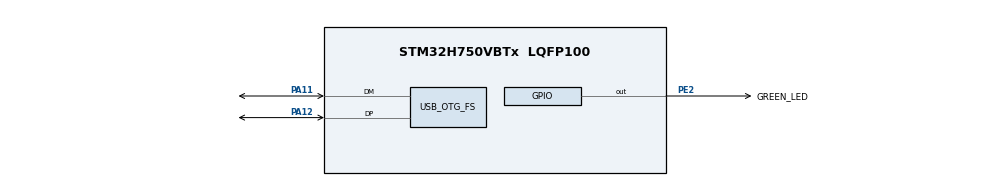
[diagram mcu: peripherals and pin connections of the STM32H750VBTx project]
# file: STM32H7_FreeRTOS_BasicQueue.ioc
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FREERTOS.Queues01=messageQueue,4,uint8_t,0,Dynamic,NULL,NULL
FREERTOS.Tasks01=receive,24,256,receiveTask,Default,NULL,Dynamic,NULL,NULL;transmit,24,256,transmitTask,Default,NULL,Dynamic,NULL,NULL
Mcu.Family=STM32H7
Mcu.Name=STM32H750VBTx
Mcu.Package=LQFP100
NVIC.OTG_FS_IRQn=true\:5\:0\:false\:false\:true\:true\:false\:true\:true
NVIC.PriorityGroup=NVIC_PRIORITYGROUP_4
NVIC.TIM6_DAC_IRQn=true\:15\:0\:false\:false\:true\:false\:false\:true\:true
NVIC.TimeBase=TIM6_DAC_IRQn
NVIC.TimeBaseIP=TIM6
PA11.Mode=Device_Only
PA11.Signal=USB_OTG_FS_DM
PA12.Mode=Device_Only
PA12.Signal=USB_OTG_FS_DP
PE2.GPIO_Label=GREEN_LED
PE2.Signal=GPIO_Output
ProjectManager.HeapSize=0x200
ProjectManager.StackSize=0x400
ProjectManager.TargetToolchain=Makefile
RCC.ADCFreq_Value=129000000
RCC.APB1Freq_Value=64000000
RCC.APB2Freq_Value=64000000
RCC.APB3Freq_Value=64000000
RCC.APB4Freq_Value=64000000
RCC.CortexFreq_Value=64000000
RCC.HCLKFreq_Value=64000000
RCC.SYSCLKFreq_VALUE=64000000
RCC.USBCLockSelection=RCC_USBCLKSOURCE_HSI48
RCC.USBFreq_Value=48000000
USB_DEVICE.CLASS_NAME_FS=CDC
USB_DEVICE.VirtualMode-CDC_FS=Cdc
USB_DEVICE.VirtualModeFS=Cdc_FS
USB_OTG_FS.VirtualMode=Device_Only
VP_FREERTOS_VS_CMSIS_V2.Mode=CMSIS_V2
VP_SYS_VS_tim6.Mode=TIM6
VP_USB_DEVICE_VS_USB_DEVICE_CDC_FS.Mode=CDC_FS
board=custom

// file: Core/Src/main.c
/* USER CODE BEGIN Header */
/**
  ******************************************************************************
  * @file           : main.c
  * @brief          : Main program body
  ******************************************************************************
  * @attention
  *
  * Copyright (c) 2024 STMicroelectronics.
  * All rights reserved.
  *
  * This software is licensed under terms that can be found in the LICENSE file
  * in the root directory of this software component.
  * If no LICENSE file comes with this software, it is provided AS-IS.
  *
  ******************************************************************************
  */
/* USER CODE END Header */
#include "main.h"
#include "cmsis_os.h"
#include "usb_device.h"
#include "usbd_cdc_if.h"

/* Definitions for receive */
osThreadId_t receiveHandle;
const osThreadAttr_t receive_attributes = {
  .name = "receive",
  .stack_size = 256 * 4,
  .priority = (osPriority_t) osPriorityNormal,
};
/* Definitions for transmit */
osThreadId_t transmitHandle;
const osThreadAttr_t transmit_attributes = {
  .name = "transmit",
  .stack_size = 256 * 4,
  .priority = (osPriority_t) osPriorityNormal,
};
/* Definitions for messageQueue */
osMessageQueueId_t messageQueueHandle;
const osMessageQueueAttr_t messageQueue_attributes = {
  .name = "messageQueue"
};

void SystemClock_Config(void);
static void MX_GPIO_Init(void);
void receiveTask(void *argument);
void transmitTask(void *argument);

int main(void)
{

  /* MCU Configuration--------------------------------------------------------*/

  /* Reset of all peripherals, Initializes the Flash interface and the Systick. */
  HAL_Init();

  /* Configure the system clock */
  SystemClock_Config();

  /* Initialize all configured peripherals */
  MX_GPIO_Init();

  /* Init scheduler */
  osKernelInitialize();

  /* Create the queue(s) */
  /* creation of messageQueue */
  messageQueueHandle = osMessageQueueNew (4, sizeof(uint8_t), &messageQueue_attributes);

  /* Create the thread(s) */
  /* creation of receive */
  receiveHandle = osThreadNew(receiveTask, NULL, &receive_attributes);

  /* creation of transmit */
  transmitHandle = osThreadNew(transmitTask, NULL, &transmit_attributes);

  /* Start scheduler */
  osKernelStart();

  /* We should never get here as control is now taken by the scheduler */
  /* Infinite loop */
  while (1)
  {

  }
}

void SystemClock_Config(void)
{
  RCC_OscInitTypeDef RCC_OscInitStruct = {0};
  RCC_ClkInitTypeDef RCC_ClkInitStruct = {0};

  /** Supply configuration update enable
  */
  HAL_PWREx_ConfigSupply(PWR_LDO_SUPPLY);

  /** Configure the main internal regulator output voltage
  */
  __HAL_PWR_VOLTAGESCALING_CONFIG(PWR_REGULATOR_VOLTAGE_SCALE3);

  while(!__HAL_PWR_GET_FLAG(PWR_FLAG_VOSRDY)) {}

  /** Initializes the RCC Oscillators according to the specified parameters
  * in the RCC_OscInitTypeDef structure.
  */
  RCC_OscInitStruct.OscillatorType = RCC_OSCILLATORTYPE_HSI48|RCC_OSCILLATORTYPE_HSI;
  RCC_OscInitStruct.HSIState = RCC_HSI_DIV1;
  RCC_OscInitStruct.HSICalibrationValue = RCC_HSICALIBRATION_DEFAULT;
  RCC_OscInitStruct.HSI48State = RCC_HSI48_ON;
  RCC_OscInitStruct.PLL.PLLState = RCC_PLL_NONE;
  if (HAL_RCC_OscConfig(&RCC_OscInitStruct) != HAL_OK)
  {
    Error_Handler();
  }

  /** Initializes the CPU, AHB and APB buses clocks
  */
  RCC_ClkInitStruct.ClockType = RCC_CLOCKTYPE_HCLK|RCC_CLOCKTYPE_SYSCLK
                              |RCC_CLOCKTYPE_PCLK1|RCC_CLOCKTYPE_PCLK2
                              |RCC_CLOCKTYPE_D3PCLK1|RCC_CLOCKTYPE_D1PCLK1;
  RCC_ClkInitStruct.SYSCLKSource = RCC_SYSCLKSOURCE_HSI;
  RCC_ClkInitStruct.SYSCLKDivider = RCC_SYSCLK_DIV1;
  RCC_ClkInitStruct.AHBCLKDivider = RCC_HCLK_DIV1;
  RCC_ClkInitStruct.APB3CLKDivider = RCC_APB3_DIV1;
  RCC_ClkInitStruct.APB1CLKDivider = RCC_APB1_DIV1;
  RCC_ClkInitStruct.APB2CLKDivider = RCC_APB2_DIV1;
  RCC_ClkInitStruct.APB4CLKDivider = RCC_APB4_DIV1;

  if (HAL_RCC_ClockConfig(&RCC_ClkInitStruct, FLASH_LATENCY_1) != HAL_OK)
  {
    Error_Handler();
  }
}

static void MX_GPIO_Init(void)
{
  GPIO_InitTypeDef GPIO_InitStruct = {0};

  /* GPIO Ports Clock Enable */
  __HAL_RCC_GPIOE_CLK_ENABLE();
  __HAL_RCC_GPIOA_CLK_ENABLE();

  /*Configure GPIO pin Output Level */
  HAL_GPIO_WritePin(GREEN_LED_GPIO_Port, GREEN_LED_Pin, GPIO_PIN_RESET);

  /*Configure GPIO pin : GREEN_LED_Pin */
  GPIO_InitStruct.Pin = GREEN_LED_Pin;
  GPIO_InitStruct.Mode = GPIO_MODE_OUTPUT_PP;
  GPIO_InitStruct.Pull = GPIO_NOPULL;
  GPIO_InitStruct.Speed = GPIO_SPEED_FREQ_LOW;
  HAL_GPIO_Init(GREEN_LED_GPIO_Port, &GPIO_InitStruct);

}

void receiveTask(void *argument)
{
  /* init code for USB_DEVICE */
  MX_USB_DEVICE_Init();
  /* USER CODE BEGIN 5 */
  uint8_t res = 0;
  char buffer[50];
  /* Infinite loop */
  for(;;)
  {
    snprintf(buffer, sizeof(buffer), "Data: %d\r\n", res);
    CDC_Transmit_FS((uint8_t*)buffer, strlen(buffer));
    osMessageQueueGet(messageQueueHandle, &res, NULL, osWaitForever);
    osDelay(1000);
  }
  /* USER CODE END 5 */
}

void transmitTask(void *argument)
{
  /* USER CODE BEGIN transmitTask */
  uint8_t x = 0;
  /* Infinite loop */
  for(;;)
  {
    osMessageQueuePut(messageQueueHandle, &x, 0, osWaitForever);
    if(++x>9){
      x=0;
    }
    osDelay(1000);
  }
  /* USER CODE END transmitTask */
}

void HAL_TIM_PeriodElapsedCallback(TIM_HandleTypeDef *htim)
{
  if (htim->Instance == TIM6) {
    HAL_IncTick();
  }
}

void Error_Handler(void)
{
  __disable_irq();
  while (1)
  {
  }
}
